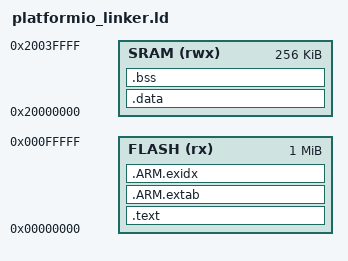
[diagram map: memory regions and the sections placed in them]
/*
 * TM4C1294 linker script for the PlatformIO/GCC build.
 *
 * Maps the vector table, code and read-only data to flash, and writable data to SRAM.
 */

MEMORY
{
    FLASH (rx)  : ORIGIN = 0x00000000, LENGTH = 1024K
    SRAM  (rwx) : ORIGIN = 0x20000000, LENGTH = 256K
}

SECTIONS
{
    .text :
    {
        _text = .;
        KEEP(*(.isr_vector))
        *(.text*)
        *(.rodata*)
        _etext = .;
    } > FLASH

    .ARM.extab :
    {
        *(.ARM.extab*)
    } > FLASH

    .ARM.exidx :
    {
        __exidx_start = .;
        *(.ARM.exidx*)
        __exidx_end = .;
    } > FLASH

    .data : AT(ADDR(.ARM.exidx) + SIZEOF(.ARM.exidx))
    {
        _data = .;
        _ldata = LOADADDR(.data);
        *(vtable)
        *(.data*)
        _edata = .;
    } > SRAM

    .bss :
    {
        _bss = .;
        *(.bss*)
        *(COMMON)
        _ebss = .;
    } > SRAM
}

